# STM32G474xx register map
File version: 1.5
CPU: CM4 r0p1, little endian, MPU, FPU, 4 interrupt priority bits
Registers are 32-bit, read-write, reset 0x0 unless marked. A register's access mark holds for its fields unless they carry their own. Offsets are from the block's base; [hi:lo] are bit positions.

## FDCAN
Base 0x4000A400
Same registers: FDCAN1 0x40006400, FDCAN2 0x40006800, FDCAN3 0x40006C00
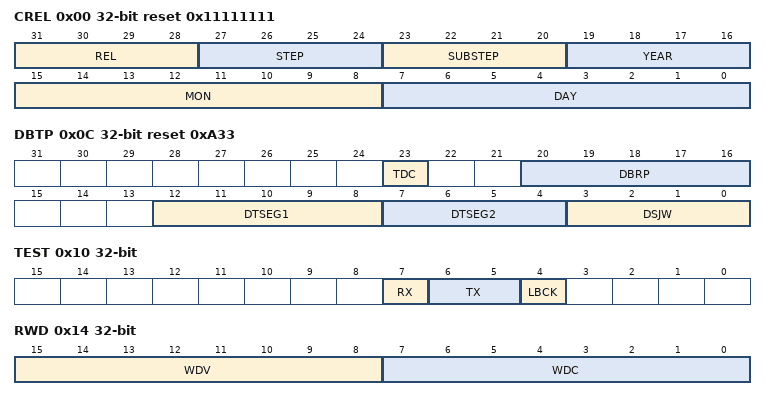
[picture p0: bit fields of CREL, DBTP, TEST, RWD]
0x00 CREL ro reset 0x11111111 — FDCAN Core Release Register
  [31:28] REL, [27:24] STEP, [23:20] SUBSTEP, [19:16] YEAR, [15:8] MON, [7:0] DAY
0x04 ENDN ro reset 0x87654321 — FDCAN Core Release Register
  [31:0] ETV
0x0C DBTP access per field reset 0xA33 — This register is only writable if bits CCCR.CCE and CCCR.INIT are set. The CAN bit time may be programed in the range of 4 to 25 time quanta. The CAN time quantum may be programmed in the range of 1 to 1024 FDCAN clock periods. tq = (DBRP + 1) FDCAN clock period. DTSEG1 is the sum of Prop_Seg and Phase_Seg1. DTSEG2 is Phase_Seg2. Therefore the length of the bit time is (programmed values) [DTSEG1 + DTSEG2 + 3] tq or (functional values) [Sync_Seg + Prop_Seg + Phase_Seg1 + Phase_Seg2] tq. The Information Processing Time (IPT) is zero, meaning the data for the next bit is available at the first clock edge after the sample point.
  [23] TDC ro, [20:16] DBRP rw, [12:8] DTSEG1 wo, [7:4] DTSEG2 rw, [3:0] DSJW rw
0x10 TEST — Write access to the Test Register has to be enabled by setting bit CCCR[TEST] to 1 . All Test Register functions are set to their reset values when bit CCCR[TEST] is reset. Loop Back mode and software control of Tx pin FDCANx_TX are hardware test modes. Programming TX differently from 00 may disturb the message transfer on the CAN bus.
  [7] RX, [6:5] TX, [4] LBCK
0x14 RWD access per field — The RAM Watchdog monitors the READY output of the Message RAM. A Message RAM access starts the Message RAM Watchdog Counter with the value configured by the RWD[WDC] bits. The counter is reloaded with RWD[WDC] bits when the Message RAM signals successful completion by activating its READY output. In case there is no response from the Message RAM until the counter has counted down to 0, the counter stops and interrupt flag IR[WDI] bit is set. The RAM Watchdog Counter is clocked by the fdcan_pclk clock.
  [15:8] WDV ro, [7:0] WDC rw
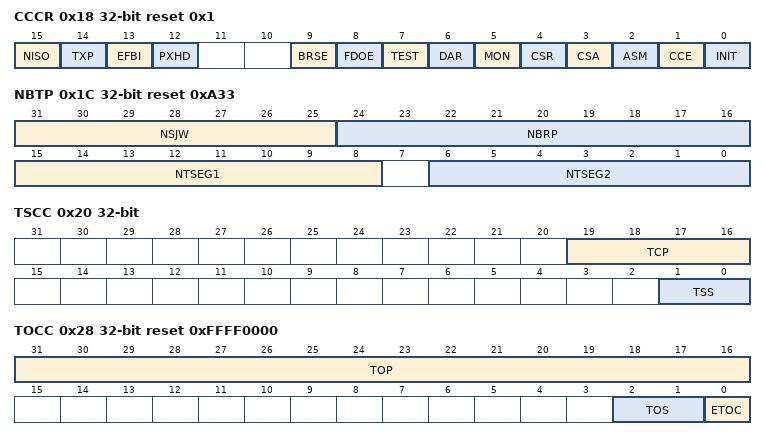
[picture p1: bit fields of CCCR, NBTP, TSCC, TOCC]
0x18 CCCR reset 0x1 — For details about setting and resetting of single bits see Software initialization.
  [15] NISO, [14] TXP, [13] EFBI, [12] PXHD, [9] BRSE, [8] FDOE, [7] TEST, [6] DAR, [5] MON, [4] CSR, [3] CSA, [2] ASM, [1] CCE, [0] INIT
0x1C NBTP reset 0xA33 — FDCAN_NBTP
  [31:25] NSJW, [24:16] NBRP, [15:8] NTSEG1, [6:0] NTSEG2
0x20 TSCC — FDCAN Timestamp Counter Configuration Register
  [19:16] TCP, [1:0] TSS
0x24 TSCV ro — FDCAN Timestamp Counter Value Register
  [15:0] TSC
0x28 TOCC access per field reset 0xFFFF0000 — FDCAN Timeout Counter Configuration Register
  [31:16] TOP rw, [2:1] TOS wo, [0] ETOC rw
0x2C TOCV ro reset 0xFFFF — FDCAN Timeout Counter Value Register
  [15:0] TOC
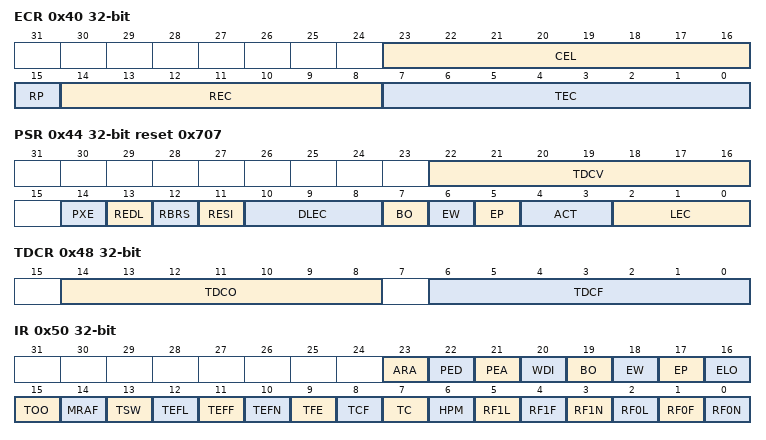
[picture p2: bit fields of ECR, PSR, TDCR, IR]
0x40 ECR ro — FDCAN Error Counter Register
  [23:16] CEL, [15] RP, [14:8] REC, [7:0] TEC
0x44 PSR access per field reset 0x707 — FDCAN Protocol Status Register
  [22:16] TDCV rw, [14] PXE rw, [13] REDL rw, [12] RBRS rw, [11] RESI rw, [10:8] DLEC wo, [7] BO rw, [6] EW rw, [5] EP rw, [4:3] ACT wo, [2:0] LEC rw
0x48 TDCR — FDCAN Transmitter Delay Compensation Register
  [14:8] TDCO, [6:0] TDCF
0x50 IR — The flags are set when one of the listed conditions is detected (edge-sensitive). The flags remain set until the Host clears them. A flag is cleared by writing a 1 to the corresponding bit position. Writing a 0 has no effect. A hard reset will clear the register. The configuration of IE controls whether an interrupt is generated. The configuration of ILS controls on which interrupt line an interrupt is signaled.
  [23] ARA, [22] PED, [21] PEA, [20] WDI, [19] BO, [18] EW, [17] EP, [16] ELO, [15] TOO, [14] MRAF, [13] TSW, [12] TEFL, [11] TEFF, [10] TEFN, [9] TFE, [8] TCF, [7] TC, [6] HPM, [5] RF1L, [4] RF1F, [3] RF1N, [2] RF0L, [1] RF0F, [0] RF0N
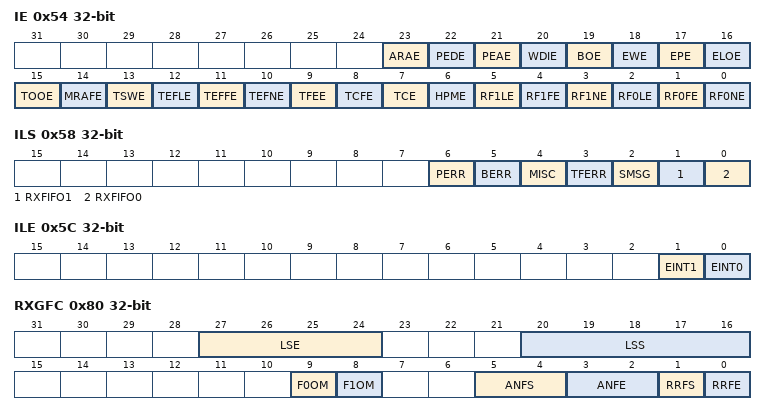
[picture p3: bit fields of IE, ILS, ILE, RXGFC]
0x54 IE — The settings in the Interrupt Enable register determine which status changes in the Interrupt Register will be signaled on an interrupt line.
  [23] ARAE, [22] PEDE, [21] PEAE, [20] WDIE, [19] BOE, [18] EWE, [17] EPE, [16] ELOE, [15] TOOE, [14] MRAFE, [13] TSWE, [12] TEFLE, [11] TEFFE, [10] TEFNE, [9] TFEE, [8] TCFE, [7] TCE, [6] HPME, [5] RF1LE, [4] RF1FE, [3] RF1NE, [2] RF0LE, [1] RF0FE, [0] RF0NE
0x58 ILS — The Interrupt Line Select register assigns an interrupt generated by a specific interrupt flag from the Interrupt Register to one of the two module interrupt lines. For interrupt generation the respective interrupt line has to be enabled via ILE[EINT0] and ILE[EINT1].
  [6] PERR, [5] BERR, [4] MISC, [3] TFERR, [2] SMSG, [1] RXFIFO1, [0] RXFIFO0
0x5C ILE — Each of the two interrupt lines to the CPU can be enabled/disabled separately by programming bits EINT0 and EINT1.
  [1] EINT1, [0] EINT0
0x80 RXGFC access per field — Global settings for Message ID filtering. The Global Filter Configuration controls the filter path for standard and extended messages as described in Figure706: Standard Message ID filter path and Figure707: Extended Message ID filter path.
  [27:24] LSE rw
  [20:16] LSS rw
  [9] F0OM rw — F1OM
  [8] F1OM rw
  [5:4] ANFS wo
  [3:2] ANFE wo
  [1] RRFS rw
  [0] RRFE rw
0x84 XIDAM reset 0x1FFFFFFF — FDCAN Extended ID and Mask Register
  [28:0] EIDM
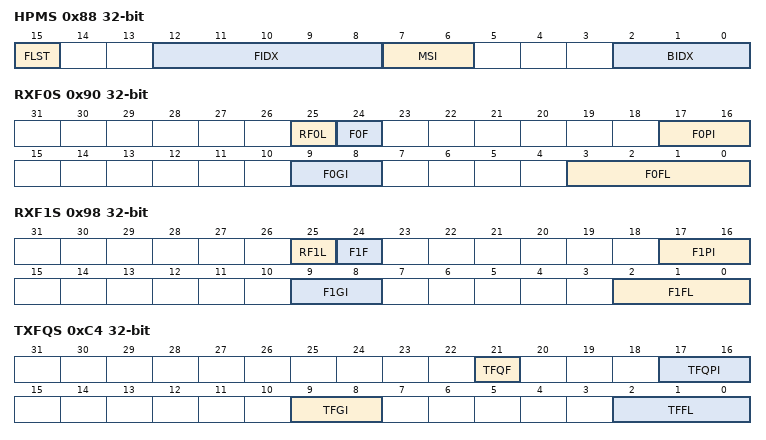
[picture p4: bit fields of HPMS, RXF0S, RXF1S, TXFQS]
0x88 HPMS ro — This register is updated every time a Message ID filter element configured to generate a priority event match. This can be used to monitor the status of incoming high priority messages and to enable fast access to these messages.
  [15] FLST, [12:8] FIDX, [7:6] MSI, [2:0] BIDX
0x90 RXF0S — FDCAN Rx FIFO 0 Status Register
  [25] RF0L, [24] F0F, [17:16] F0PI, [9:8] F0GI, [3:0] F0FL
0x94 RXF0A — CAN Rx FIFO 0 Acknowledge Register
  [2:0] F0AI
0x98 RXF1S ro — FDCAN Rx FIFO 1 Status Register
  [25] RF1L, [24] F1F, [17:16] F1PI, [9:8] F1GI, [2:0] F1FL
0x9C RXF1A — FDCAN Rx FIFO 1 Acknowledge Register
  [2:0] F1AI
0xC0 TXBC — FDCAN Tx Buffer Configuration Register
  [30] TFQM
0xC4 TXFQS ro — The Tx FIFO/Queue status is related to the pending Tx requests listed in register TXBRP. Therefore the effect of Add/Cancellation requests may be delayed due to a running Tx scan (TXBRP not yet updated).
  [21] TFQF, [17:16] TFQPI, [9:8] TFGI, [2:0] TFFL
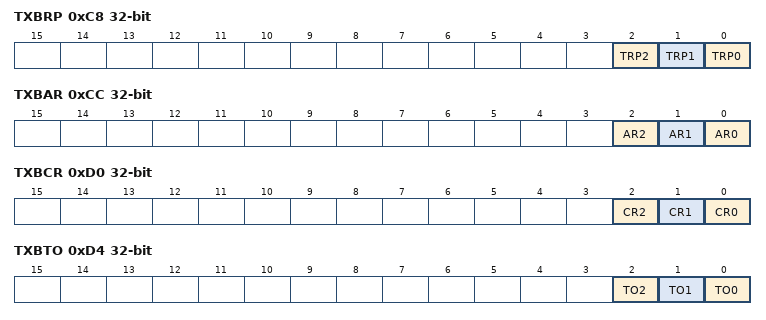
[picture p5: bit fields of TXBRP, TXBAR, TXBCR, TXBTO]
0xC8 TXBRP ro — FDCAN Tx Buffer Request Pending Register
  [2] TRP2, [1] TRP1, [0] TRP0
0xCC TXBAR — FDCAN Tx Buffer Add Request Register
  [2] AR2, [1] AR1, [0] AR0
0xD0 TXBCR — FDCAN Tx Buffer Cancellation Request Register
  [2] CR2 — TRP2
  [1] CR1 — TRP1
  [0] CR0 — TRP0
0xD4 TXBTO ro — FDCAN Tx Buffer Transmission Occurred Register
  [2] TO2 — TRP2
  [1] TO1 — TRP1
  [0] TO0 — TRP0
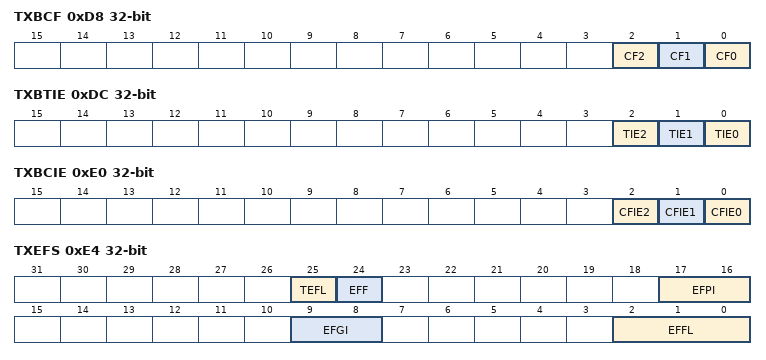
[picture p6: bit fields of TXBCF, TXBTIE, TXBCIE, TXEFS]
0xD8 TXBCF ro — FDCAN Tx Buffer Cancellation Finished Register
  [2] CF2 — TRP2
  [1] CF1 — TRP1
  [0] CF0 — TRP0
0xDC TXBTIE — FDCAN Tx Buffer Transmission Interrupt Enable Register
  [2] TIE2 — TRP2
  [1] TIE1 — TRP1
  [0] TIE0 — TRP0
0xE0 TXBCIE — FDCAN Tx Buffer Cancellation Finished Interrupt Enable Register
  [2] CFIE2 — TRP2
  [1] CFIE1 — TRP1
  [0] CFIE0 — TRP0
0xE4 TXEFS ro — FDCAN Tx Event FIFO Status Register
  [25] TEFL, [24] EFF, [17:16] EFPI, [9:8] EFGI, [2:0] EFFL
0xE8 TXEFA — FDCAN Tx Event FIFO Acknowledge Register
  [1:0] EFAI
0x100 CKDIV — FDCAN CFG clock divider register
  [3:0] PDIV — input clock divider. the APB clock could be divided prior to be used by the CAN sub
